# XMC4300 register map
Vendor: Infineon; File version: 0.5.1 (Superset device XMC4800)
CPU: CM4 r2p0, little endian, MPU, FPU, 6 interrupt priority bits
Registers are 32-bit, read-write, reset 0x0 unless marked. A register's access mark holds for its fields unless they carry their own. Offsets are from the block's base; [hi:lo] are bit positions; 'fields as' and 'values as' point back to an identical list.

## USB0 — Universal Serial Bus
Base 0x50040000
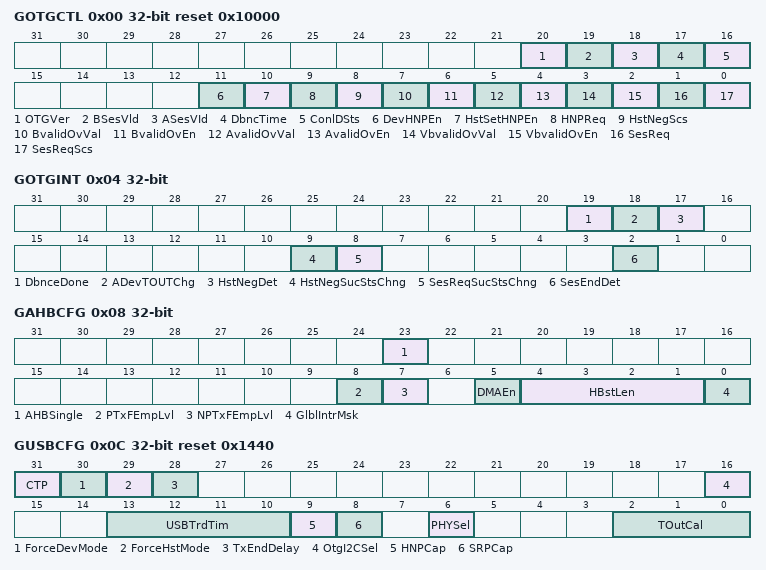
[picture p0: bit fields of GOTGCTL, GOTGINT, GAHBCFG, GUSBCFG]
0x00 GOTGCTL access per field reset 0x10000 — Control and Status Register
  [20] OTGVer rw — OTG Version
    0=OTG Version 1.3. In this version the core supports Data line pulsing and VBus pulsing for SRP.; 1=OTG Version 2.0. In this version the core supports only Data line pulsing for SRP.
  [19] BSesVld ro — B-Session Valid
    0=B-session is not valid; 1=B-session is valid
  [18] ASesVId ro — A-Session Valid
    0=A-session is not valid; 1=A-session is valid
  [17] DbncTime ro — Long/Short Debounce Time
    0=Long debounce time, used for physical connections (100 ms + 2.5 us); 1=Short debounce time, used for soft connections (2.5 us)
  [16] ConlDSts ro — Connector ID Status
    0=The USB core is in A-Device mode; 1=The USB core is in B-Device mode
  [11] DevHNPEn rw — Device HNP Enabled
    0=HNP is not enabled in the application; 1=HNP is enabled in the application
  [10] HstSetHNPEn rw — Host Set HNP Enable
    0=Host Set HNP is not enabled; 1=Host Set HNP is enabled
  [9] HNPReq rw — HNP Request
    0=No HNP request; 1=HNP request
  [8] HstNegScs ro — Host Negotiation Success
    0=Host negotiation failure; 1=Host negotiation success
  [7] BvalidOvVal rw — B-Peripheral Session Valid Override Value
    0=Bvalid value is 0# when GOTGCTL.BvalidOvEn = 1; 1=Bvalid value is 1# when GOTGCTL.BvalidOvEn = 1
  [6] BvalidOvEn rw — B-Peripheral Session Valid Override Enable
    0=Override is disabled and Bvalid signal from the PHY is used internally by the core; 1=Internally Bvalid received from the PHY is overridden with GOTGCTL.BvalidOvVal
  [5] AvalidOvVal rw — A-Peripheral Session Valid Override Value
    0=Avalid value is 0# when GOTGCTL.AvalidOvEn = 1; 1=Avalid value is 1# when GOTGCTL.AvalidOvEn = 1
  [4] AvalidOvEn rw — A-Peripheral Session Valid Override Enable
    0=Override is disabled and Avalid signal from the PHY is used internally by the core; 1=Internally Avalid received from the PHY is overridden with GOTGCTL.AvalidOvVal
  [3] VbvalidOvVal rw — VBUS Valid Override Value
    0=vbusvalid value is 0# when GOTGCTL.VbvalidOvEn = 1; 1=vbusvalid value is 1# when GOTGCTL.VbvalidOvEn = 1
  [2] VbvalidOvEn rw — VBUS Valid Override Enable
    0=Override is disabled and vbus valid signal from the PHY is used internally by the core; 1=Internally vbus valid received from the PHY is overridden with GOTGCTL.VbvalidOvVal
  [1] SesReq rw — Session Request
    0=No session request; 1=Session request
  [0] SesReqScs ro — Session Request Success
    0=Session request failure; 1=Session request success
0x04 GOTGINT — OTG Interrupt Register
  [19] DbnceDone — Debounce Done
  [18] ADevTOUTChg — A-Device Timeout Change
  [17] HstNegDet — Host Negotiation Detected
  [9] HstNegSucStsChng — Host Negotiation Success Status Change
  [8] SesReqSucStsChng — Session Request Success Status Change
  [2] SesEndDet — Session End Detected
0x08 GAHBCFG — AHB Configuration Register
  [23] AHBSingle — AHB Single Support
    0=The remaining data in a transfer is sent using INCR burst size. This is the default mode.; 1=The remaining data in a transfer is sent using single burst size
  [8] PTxFEmpLvl — Periodic TxFIFO Empty Level
    0=GINTSTS.PTxFEmp interrupt indicates that the Periodic TxFIFO is half empty; 1=GINTSTS.PTxFEmp interrupt indicates that the Periodic TxFIFO is completely empty
  [7] NPTxFEmpLvl — Non-Periodic TxFIFO Empty Level
    0=DIEPINTx.TxFEmp interrupt indicates that the IN Endpoint TxFIFO is half empty; 1=DIEPINTx.TxFEmp interrupt indicates that the IN Endpoint TxFIFO is completely empty
  [5] DMAEn — DMA Enable
    0=Core operates in Slave mode; 1=Core operates in a DMA mode
  [4:1] HBstLen — Burst Length/Type
    0=Single; 1=INCR; 3=INCR4; 5=INCR8; 7=INCR16
  [0] GlblIntrMsk — Global Interrupt Mask
    0=Mask the interrupt assertion to the application; 1=Unmask the interrupt assertion to the application
0x0C GUSBCFG access per field reset 0x1440 — USB Configuration Register
  [31] CTP rw — Corrupt Tx packet
  [30] ForceDevMode rw — Force Device Mode
    0=Normal Mode; 1=Force Device Mode
  [29] ForceHstMode rw — Force Host Mode
    0=Normal Mode; 1=Force Host Mode
  [28] TxEndDelay rw
    0=Normal mode; 1=Introduce Tx end delay timers
  [16] OtgI2CSel rw — UTMIFS Interface Select
    0=UTMI USB 1.1 Full-Speed interface for OTG signals
  [13:10] USBTrdTim rw — USB Turnaround Time
  [9] HNPCap rw — HNP-Capable
    0=HNP capability is not enabled; 1=HNP capability is enabled
  [8] SRPCap rw — SRP-Capable
    0=SRP capability is not enabled; 1=SRP capability is enabled
  [6] PHYSel ro — USB 1.1 Full-Speed Serial Transceiver Select
    1=USB 1.1 full-speed serial transceiver
  [2:0] TOutCal rw — FS Timeout Calibration
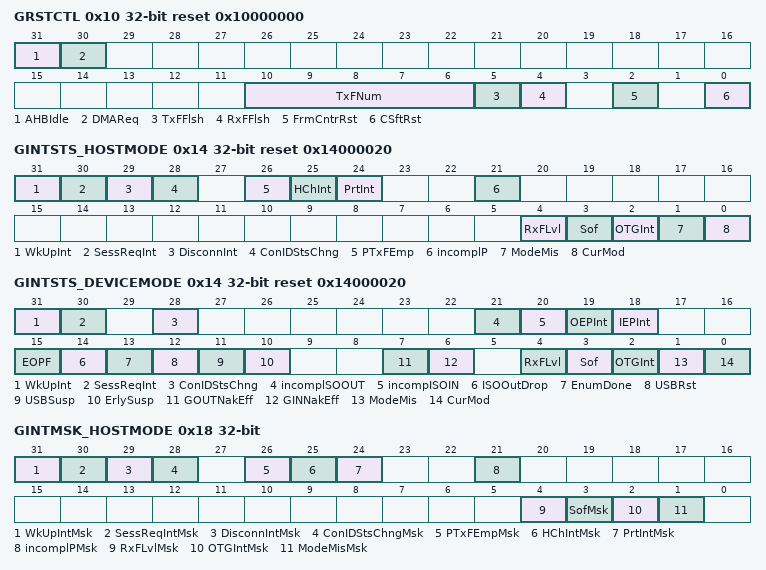
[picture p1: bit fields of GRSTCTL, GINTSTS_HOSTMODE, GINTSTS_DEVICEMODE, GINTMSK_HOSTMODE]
0x10 GRSTCTL access per field reset 0x10000000 — Reset Register
  [31] AHBIdle ro — AHB Master Idle
  [30] DMAReq ro — DMA Request Signal
  [10:6] TxFNum rw — TxFIFO Number
    0=Non-periodic TxFIFO flush in Host mode or Tx FIFO 0 flush in device mode; 1=Periodic TxFIFO flush in Host mode or Tx FIFO 1 flush in device mode; 2=Tx FIFO 2 flush in device mode; 15=Tx FIFO 15 flush in device mode; 16=Flush all the transmit FIFOs in device or host mode
  [5] TxFFlsh rw — TxFIFO Flush
  [4] RxFFlsh rw — RxFIFO Flush
  [2] FrmCntrRst rw — Host Frame Counter Reset
  [0] CSftRst rw — Core Soft Reset
0x14 GINTSTS_HOSTMODE access per field reset 0x14000020 — Interrupt Register [HOSTMODE]
  [31] WkUpInt rw — Resume/Remote Wakeup Detected Interrupt
  [30] SessReqInt rw — Session Request/New Session Detected Interrupt
  [29] DisconnInt rw — Disconnect Detected Interrupt
  [28] ConIDStsChng rw — Connector ID Status Change
  [26] PTxFEmp ro — Periodic TxFIFO Empty
  [25] HChInt ro — Host Channels Interrupt
  [24] PrtInt ro — Host Port Interrupt
  [21] incomplP rw — Incomplete Periodic Transfer
  [4] RxFLvl ro — RxFIFO Non-Empty
  [3] Sof rw — Start of Frame
  [2] OTGInt ro — OTG Interrupt
  [1] ModeMis rw — Mode Mismatch Interrupt
  [0] CurMod ro — Current Mode of Operation
    0=Device mode; 1=Host mode
0x14 GINTSTS_DEVICEMODE access per field reset 0x14000020 (alternate view of GINTSTS_HOSTMODE) — Interrupt Register [DEVICEMODE]
  [31] WkUpInt rw — Resume/Remote Wakeup Detected Interrupt
  [30] SessReqInt rw — Session Request/New Session Detected Interrupt
  [28] ConIDStsChng rw — Connector ID Status Change
  [21] incomplSOOUT rw — Incomplete Isochronous OUT Transfer
  [20] incompISOIN rw — Incomplete Isochronous IN Transfer
  [19] OEPInt ro — OUT Endpoints Interrupt
  [18] IEPInt ro — IN Endpoints Interrupt
  [15] EOPF rw — End of Periodic Frame Interrupt
  [14] ISOOutDrop rw — Isochronous OUT Packet Dropped Interrupt
  [13] EnumDone rw — Enumeration Done
  [12] USBRst rw — USB Reset
  [11] USBSusp rw — USB Suspend
  [10] ErlySusp rw — Early Suspend
  [7] GOUTNakEff ro — Global OUT NAK Effective
  [6] GINNakEff ro — Global IN Non-Periodic NAK Effective
  [4] RxFLvl ro — RxFIFO Non-Empty
  [3] Sof rw — Start of Frame
  [2] OTGInt ro — OTG Interrupt
  [1] ModeMis rw — Mode Mismatch Interrupt
  [0] CurMod ro — Current Mode of Operation
    0=Device mode; 1=Host mode
0x18 GINTMSK_HOSTMODE — Interrupt Mask Register [HOSTMODE]
  [31] WkUpIntMsk — Resume/Remote Wakeup Detected Interrupt Mask
  [30] SessReqIntMsk — Session Request/New Session Detected Interrupt Mask
  [29] DisconnIntMsk — Disconnect Detected Interrupt Mask
  [28] ConIDStsChngMsk — Connector ID Status Change Mask
  [26] PTxFEmpMsk — Periodic TxFIFO Empty Mask
  [25] HChIntMsk — Host Channels Interrupt Mask
  [24] PrtIntMsk — Host Port Interrupt Mask
  [21] incomplPMsk — Incomplete Periodic Transfer Mask
  [4] RxFLvlMsk — Receive FIFO Non-Empty Mask
  [3] SofMsk — Start of Frame Mask
  [2] OTGIntMsk — OTG Interrupt Mask
  [1] ModeMisMsk — Mode Mismatch Interrupt Mask
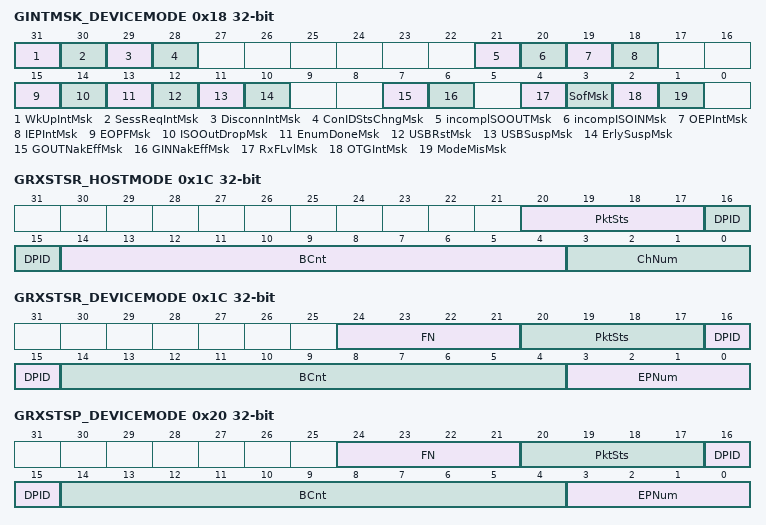
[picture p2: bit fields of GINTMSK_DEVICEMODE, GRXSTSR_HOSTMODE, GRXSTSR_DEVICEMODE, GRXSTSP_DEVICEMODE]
0x18 GINTMSK_DEVICEMODE (alternate view of GINTMSK_HOSTMODE) — Interrupt Mask Register [DEVICEMODE]
  [31] WkUpIntMsk — Resume/Remote Wakeup Detected Interrupt Mask
  [30] SessReqIntMsk — Session Request/New Session Detected Interrupt Mask
  [29] DisconnIntMsk — Disconnect Detected Interrupt Mask
  [28] ConIDStsChngMsk — Connector ID Status Change Mask
  [21] incomplSOOUTMsk — Incomplete Isochronous OUT Transfer Mask
  [20] incompISOINMsk — Incomplete Isochronous IN Transfer Mask
  [19] OEPIntMsk — OUT Endpoints Interrupt Mask
  [18] IEPIntMsk — IN Endpoints Interrupt Mask
  [15] EOPFMsk — End of Periodic Frame Interrupt Mask
  [14] ISOOutDropMsk — Isochronous OUT Packet Dropped Interrupt Mask
  [13] EnumDoneMsk — Enumeration Done Mask
  [12] USBRstMsk — USB Reset Mask
  [11] USBSuspMsk — USB Suspend Mask
  [10] ErlySuspMsk — Early Suspend Mask
  [7] GOUTNakEffMsk — Global OUT NAK Effective Mask
  [6] GINNakEffMsk — Global Non-periodic IN NAK Effective Mask
  [4] RxFLvlMsk — Receive FIFO Non-Empty Mask
  [3] SofMsk — Start of Frame Mask
  [2] OTGIntMsk — OTG Interrupt Mask
  [1] ModeMisMsk — Mode Mismatch Interrupt Mask
0x1C GRXSTSR_HOSTMODE ro — Receive Status Debug Read Register [HOSTMODE]
  [20:17] PktSts — Packet Status
    2=IN data packet received; 3=IN transfer completed (triggers an interrupt); 5=Data toggle error (triggers an interrupt); 7=Channel halted (triggers an interrupt)
  [16:15] DPID — Data PID
    0=DATA0; 2=DATA1; 1=DATA2; 3=MDATA
  [14:4] BCnt — Byte Count
  [3:0] ChNum — Channel Number
0x1C GRXSTSR_DEVICEMODE ro (alternate view of GRXSTSR_HOSTMODE) — Receive Status Debug Read Register [DEVICEMODE]
  [24:21] FN — Frame Number
  [20:17] PktSts — Packet Status
    1=Global OUT NAK (triggers an interrupt); 2=OUT data packet received; 3=OUT transfer completed (triggers an interrupt); 4=SETUP transaction completed (triggers an interrupt); 6=SETUP data packet received
  [16:15] DPID — Data PID
    0=DATA0; 2=DATA1; 1=DATA2; 3=MDATA
  [14:4] BCnt — Byte Count
  [3:0] EPNum — Endpoint Number
0x20 GRXSTSP_DEVICEMODE ro read-has-side-effects — Receive Status Read and Pop Register [DEVICEMODE]
  fields as GRXSTSR_DEVICEMODE
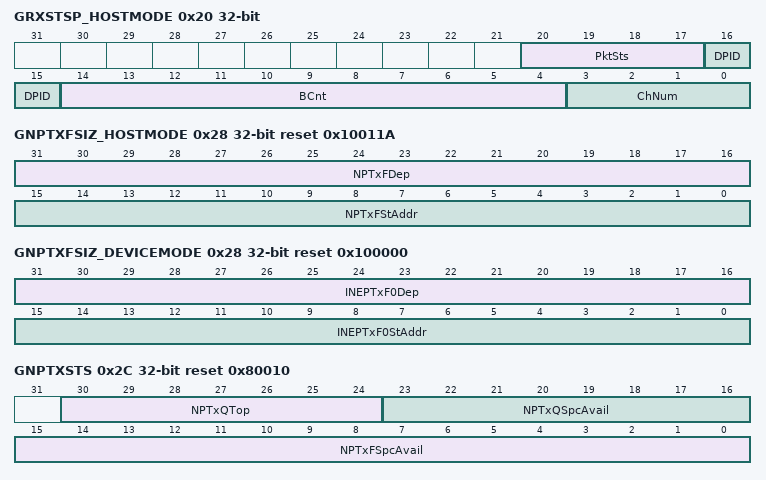
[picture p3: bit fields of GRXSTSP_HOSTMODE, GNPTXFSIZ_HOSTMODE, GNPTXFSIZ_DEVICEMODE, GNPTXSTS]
0x20 GRXSTSP_HOSTMODE ro read-has-side-effects (alternate view of GRXSTSP_DEVICEMODE) — Receive Status Read and Pop Register [HOSTMODE]
  fields as GRXSTSR_HOSTMODE
0x24 GRXFSIZ reset 0x11A — Receive FIFO Size Register
  [15:0] RxFDep — RxFIFO Depth
0x28 GNPTXFSIZ_HOSTMODE reset 0x10011A — Non-Periodic Transmit FIFO Size Register [HOSTMODE]
  [31:16] NPTxFDep — Non-periodic TxFIFO Depth
  [15:0] NPTxFStAddr — Non-periodic Transmit RAM Start Address
0x28 GNPTXFSIZ_DEVICEMODE reset 0x100000 (alternate view of GNPTXFSIZ_HOSTMODE) — Non-Periodic Transmit FIFO Size Register [DEVICEMODE]
  [31:16] INEPTxF0Dep — IN Endpoint TxFIFO 0 Depth
  [15:0] INEPTxF0StAddr — IN Endpoint FIFO0 Transmit RAM Start Address
0x2C GNPTXSTS ro reset 0x80010 — Non-Periodic Transmit FIFO/Queue Status Register
  [30:24] NPTxQTop — Top of the Non-periodic Transmit Request Queue
    0=IN/OUT token; 1=Zero-length transmit packet (device IN/host OUT); 3=Channel halt command
  [23:16] NPTxQSpcAvail — Non-periodic Transmit Request Queue Space Available
    0=Non-periodic Transmit Request Queue is full; 1=1 location available; 2=2 locations available
  [15:0] NPTxFSpcAvail — Non-periodic TxFIFO Space Avail
    0=Non-periodic TxFIFO is full; 1=1 word available; 2=2 words available
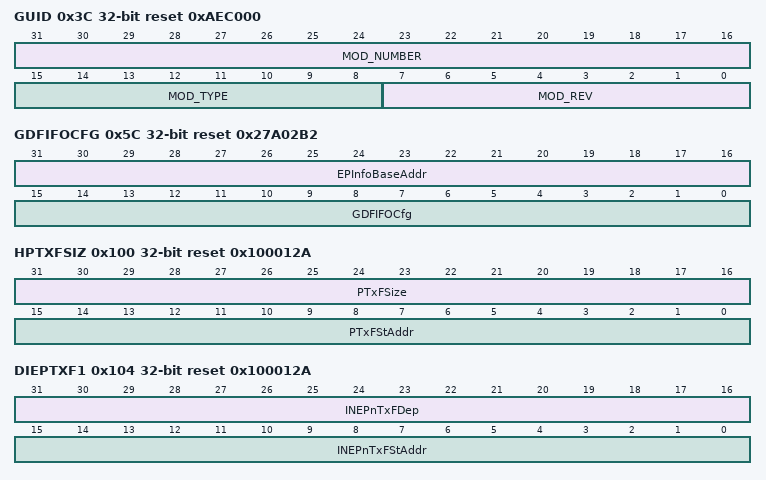
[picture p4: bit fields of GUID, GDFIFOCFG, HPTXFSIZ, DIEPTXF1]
0x3C GUID reset 0xAEC000 (reset mask 0xFFFFFF00) — USB Module Identification Register
  [31:16] MOD_NUMBER — Module Number
  [15:8] MOD_TYPE — Module Type
  [7:0] MOD_REV — Module Revision
0x5C GDFIFOCFG reset 0x27A02B2 — Global DFIFO Software Config Register
  [31:16] EPInfoBaseAddr, [15:0] GDFIFOCfg
0x100 HPTXFSIZ reset 0x100012A — Host Periodic Transmit FIFO Size Register
  [31:16] PTxFSize — Host Periodic TxFIFO Depth
  [15:0] PTxFStAddr — Host Periodic TxFIFO Start Address
0x104 DIEPTXF1 reset 0x100012A — Device IN Endpoint Transmit FIFO Size Register
  [31:16] INEPnTxFDep — IN Endpoint TxFIFO Depth
  [15:0] INEPnTxFStAddr — IN Endpoint FIFOn Transmit RAM Start Address
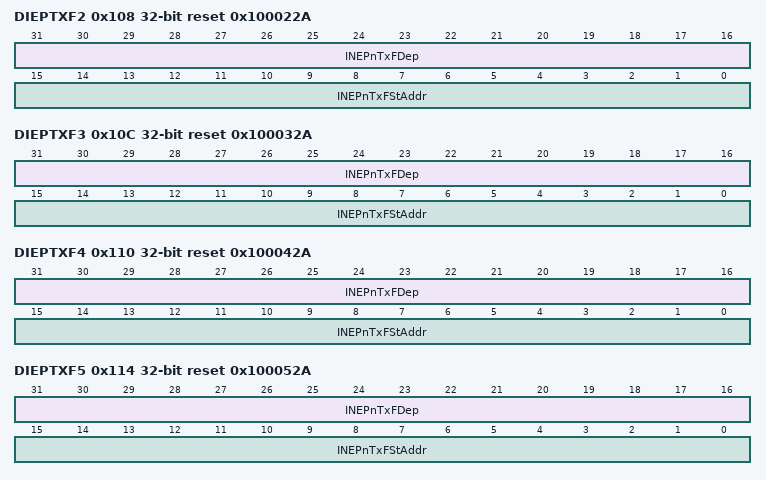
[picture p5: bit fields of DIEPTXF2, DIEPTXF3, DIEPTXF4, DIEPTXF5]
0x108 DIEPTXF2 reset 0x100022A — Device IN Endpoint Transmit FIFO Size Register
  fields as DIEPTXF1
0x10C DIEPTXF3 reset 0x100032A — Device IN Endpoint Transmit FIFO Size Register
  fields as DIEPTXF1
0x110 DIEPTXF4 reset 0x100042A — Device IN Endpoint Transmit FIFO Size Register
  fields as DIEPTXF1
0x114 DIEPTXF5 reset 0x100052A — Device IN Endpoint Transmit FIFO Size Register
  fields as DIEPTXF1
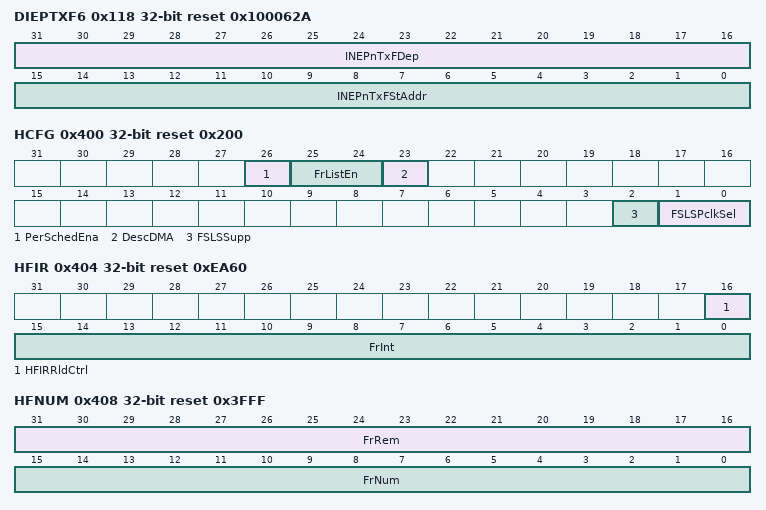
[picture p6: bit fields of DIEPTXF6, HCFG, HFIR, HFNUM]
0x118 DIEPTXF6 reset 0x100062A — Device IN Endpoint Transmit FIFO Size Register
  fields as DIEPTXF1
0x400 HCFG reset 0x200 — Host Configuration Register
  [26] PerSchedEna — Enable Periodic Scheduling
  [25:24] FrListEn — Frame List Entries
    0=8 Entries; 1=16 Entries; 2=32 Entries; 3=64 Entries
  [23] DescDMA — Enable Scatter/gather DMA in Host mode
  [2] FSLSSupp — FS-Only Support
    0=FS-only, connected device can supports also only FS; 1=FS-only, even if the connected device can support HS
  [1:0] FSLSPclkSel — FS PHY Clock Select
    1=PHY clock is running at 48 MHz
0x404 HFIR reset 0xEA60 — Host Frame Interval Register
  [16] HFIRRldCtrl — Reload Control
    0=HFIR cannot be reloaded dynamically; 1=HFIR can be dynamically reloaded during runtime
  [15:0] FrInt — Frame Interval
0x408 HFNUM access per field reset 0x3FFF — Host Frame Number/Frame Time Remaining Register
  [31:16] FrRem ro — Frame Time Remaining
  [15:0] FrNum rw — Frame Number
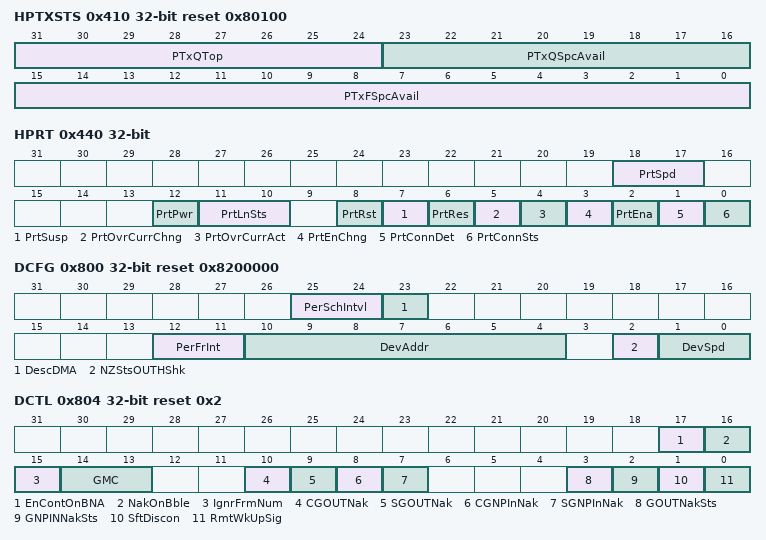
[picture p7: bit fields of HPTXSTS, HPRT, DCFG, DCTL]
0x410 HPTXSTS access per field reset 0x80100 — Host Periodic Transmit FIFO/ Queue Status Register
  [31:24] PTxQTop ro — Top of the Periodic Transmit Request Queue
  [23:16] PTxQSpcAvail ro — Periodic Transmit Request Queue Space Available
    0=Periodic Transmit Request Queue is full; 1=1 location available; 2=2 locations available
  [15:0] PTxFSpcAvail rw — Periodic Transmit Data FIFO Space Available
    0=Periodic TxFIFO is full; 1=1 word available; 2=2 words available
0x414 HAINT ro — Host All Channels Interrupt Register
  [13:0] HAINT — Channel Interrupts
0x418 HAINTMSK — Host All Channels Interrupt Mask Register
  [13:0] HAINTMsk — Channel Interrupt Mask
0x41C HFLBADDR — Host Frame List Base Address Register
  [31:0] Starting_Address
0x440 HPRT access per field — Host Port Control and Status Register
  [18:17] PrtSpd ro — Port Speed
    1=Full speed
  [12] PrtPwr rw — Port Power
    0=Power off; 1=Power on
  [11:10] PrtLnSts ro — Port Line Status
  [8] PrtRst rw — Port Reset
    0=Port not in reset; 1=Port in reset
  [7] PrtSusp rw — Port Suspend
    0=Port not in Suspend mode; 1=Port in Suspend mode
  [6] PrtRes rw — Port Resume
    0=No resume driven; 1=Resume driven
  [5] PrtOvrCurrChng rw — Port Overcurrent Change
  [4] PrtOvrCurrAct ro — Port Overcurrent Active
    0=No overcurrent condition; 1=Overcurrent condition
  [3] PrtEnChng rw — Port Enable/Disable Change
  [2] PrtEna rw — Port Enable
    0=Port disabled; 1=Port enabled
  [1] PrtConnDet rw — Port Connect Detected
  [0] PrtConnSts ro — Port Connect Status
    0=No device is attached to the port; 1=A device is attached to the port
0x800 DCFG reset 0x8200000 — Device Configuration Register
  [25:24] PerSchIntvl — Periodic Scheduling Interval
    0=25% of frame; 1=50% of frame; 2=75% of frame
  [23] DescDMA — Enable Scatter/Gather DMA in Device mode.
  [12:11] PerFrInt — Periodic Frame Interval
    0=80% of the frame interval; 1=85%; 2=90%; 3=95%
  [10:4] DevAddr — Device Address
  [2] NZStsOUTHShk — Non-Zero-Length Status OUT Handshake
    1=Send a STALL handshake on a nonzero-length status OUT transaction and do not send the received OUT packet to the application; 0=Send the received OUT packet to the application (zero-length or nonzero-length) and send a handshake based on the NAK and STALL bits for the endpoint in the Device Endpoint Control register
  [1:0] DevSpd — Device Speed
    3=Full speed (USB 1.1 transceiver clock is 48 MHz)
0x804 DCTL access per field reset 0x2 — Device Control Register
  [17] EnContOnBNA rw — Enable continue on BNA
    0=After receiving BNA interrupt, the core disables the endpoint. When the endpoint is re-enabled by the application, the core starts processing from the DOEPDMA descriptor.; 1=After receiving BNA interrupt, the core disables the endpoint. When the endpoint is re-enabled by the application, the core starts processing from the descriptor that received the BNA interrupt.
  [16] NakOnBble rw — Set NAK automatically on babble
  [15] IgnrFrmNum rw — Ignore frame number for isochronous endpoints in case of Scatter/Gather DMA
    0=Scatter/Gather enabled: The core transmits the packets only in the frame number in which they are intended to be transmitted. Scatter/Gather disabled: Periodic transfer interrupt feature is disabled; the application must program transfers for periodic endpoints every frame; 1=Scatter/Gather enabled: The core ignores the frame number, sending packets immediately as the packets are ready. Scatter/Gather disabled: Periodic transfer interrupt feature is enabled; the application can program transfers for multiple frames for periodic endpoints.
  [14:13] GMC rw — Global Multi Count
    0=Invalid; 1=1 packet; 2=2 packets; 3=3 packets
  [10] CGOUTNak wo — Clear Global OUT NAK
  [9] SGOUTNak wo — Set Global OUT NAK
  [8] CGNPInNak wo — Clear Global Non-periodic IN NAK
  [7] SGNPInNak wo — Set Global Non-periodic IN NAK
  [3] GOUTNakSts ro — Global OUT NAK Status
    0=A handshake is sent based on the FIFO Status and the NAK and STALL bit settings; 1=No data is written to the RxFIFO, irrespective of space availability. Sends a NAK handshake on all packets, except on SETUP transactions. All isochronous OUT packets are dropped.
  [2] GNPINNakSts ro — Global Non-periodic IN NAK Status
    0=A handshake is sent out based on the data availability in the transmit FIFO; 1=A NAK handshake is sent out on all non-periodic IN endpoints, irrespective of the data availability in the transmit FIFO
  [1] SftDiscon rw — Soft Disconnect
    0=Normal operation. When this bit is cleared after a soft disconnect, the core drives a device connect event to the USB host. When the device is reconnected, the USB host restarts device enumeration.; 1=The core drives a device disconnect event to the USB host
  [0] RmtWkUpSig rw — Remote Wakeup Signaling
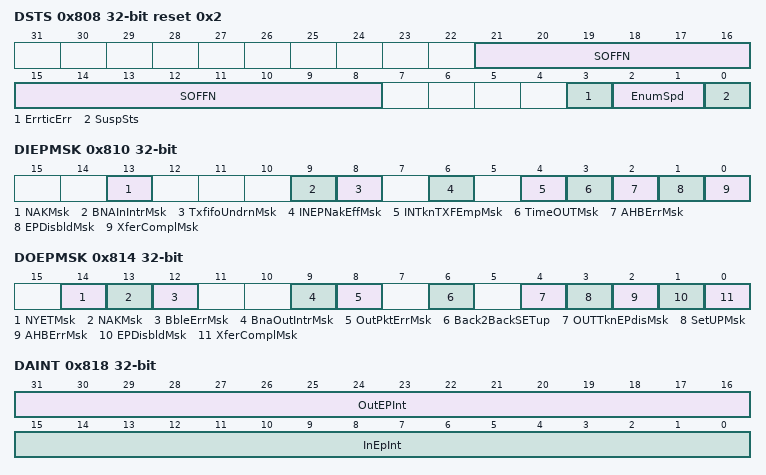
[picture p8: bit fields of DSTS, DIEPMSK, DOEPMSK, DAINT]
0x808 DSTS ro reset 0x2 — Device Status Register
  [21:8] SOFFN — Frame Number of the Received SOF
  [3] ErrticErr — Erratic Error
  [2:1] EnumSpd — Enumerated Speed
    3=Full speed (PHY clock is running at 48 MHz)
  [0] SuspSts — Suspend Status
0x810 DIEPMSK — Device IN Endpoint Common Interrupt Mask Register
  [13] NAKMsk — NAK interrupt Mask
  [9] BNAInIntrMsk — BNA Interrupt Mask
  [8] TxfifoUndrnMsk — Fifo Underrun Mask
  [6] INEPNakEffMsk — IN Endpoint NAK Effective Mask
  [4] INTknTXFEmpMsk — IN Token Received When TxFIFO Empty Mask
  [3] TimeOUTMsk — Timeout Condition Mask
  [2] AHBErrMsk — AHB Error Mask
  [1] EPDisbldMsk — Endpoint Disabled Interrupt Mask
  [0] XferComplMsk — Transfer Completed Interrupt Mask
0x814 DOEPMSK — Device OUT Endpoint Common Interrupt Mask Register
  [14] NYETMsk — NYET Interrupt Mask
  [13] NAKMsk — NAK Interrupt Mask
  [12] BbleErrMsk — Babble Interrupt Mask
  [9] BnaOutIntrMsk — BNA interrupt Mask
  [8] OutPktErrMsk — OUT Packet Error Mask
  [6] Back2BackSETup — Back-to-Back SETUP Packets Received Mask
  [4] OUTTknEPdisMsk — OUT Token Received when Endpoint Disabled Mask
  [3] SetUPMsk — SETUP Phase Done Mask
  [2] AHBErrMsk — AHB Error
  [1] EPDisbldMsk — Endpoint Disabled Interrupt Mask
  [0] XferComplMsk — Transfer Completed Interrupt Mask
0x818 DAINT ro — Device All Endpoints Interrupt Register
  [31:16] OutEPInt — OUT Endpoint Interrupt Bits
  [15:0] InEpInt — IN Endpoint Interrupt Bits
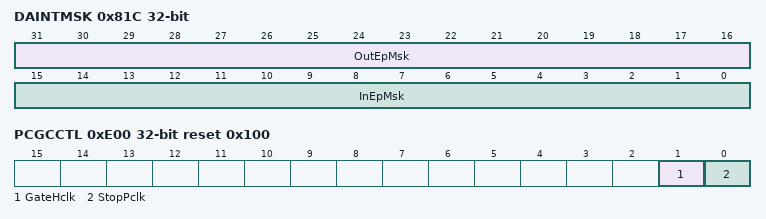
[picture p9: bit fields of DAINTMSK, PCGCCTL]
0x81C DAINTMSK — Device All Endpoints Interrupt Mask Register
  [31:16] OutEpMsk — OUT EP Interrupt Mask Bits
  [15:0] InEpMsk — IN EP Interrupt Mask Bits
0x828 DVBUSDIS reset 0x17D7 — Device VBUS Discharge Time Register
  [15:0] DVBUSDis — Device Vbus Discharge Time
0x82C DVBUSPULSE reset 0x5B8 — Device VBUS Pulsing Time Register
  [11:0] DVBUSPulse — Device Vbus Pulsing Time
0x834 DIEPEMPMSK — Device IN Endpoint FIFO Empty Interrupt Mask Register
  [15:0] InEpTxfEmpMsk — IN EP Tx FIFO Empty Interrupt Mask Bits
0xE00 PCGCCTL reset 0x100 — Power and Clock Gating Control Register
  [1] GateHclk, [0] StopPclk
